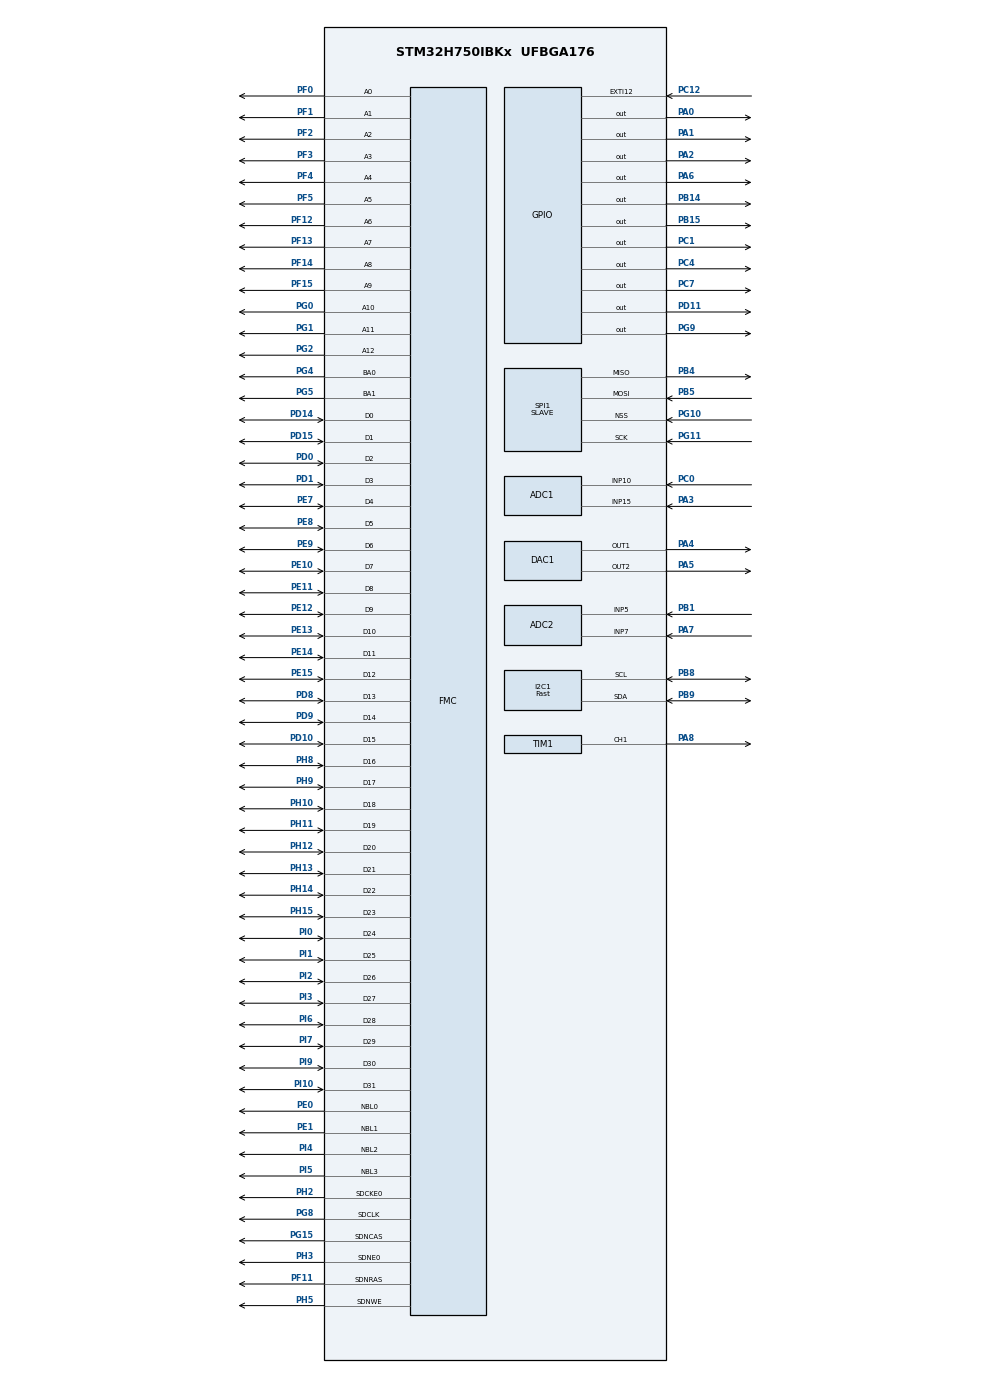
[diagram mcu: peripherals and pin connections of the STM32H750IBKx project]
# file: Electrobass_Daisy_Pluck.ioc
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ADC1.Channel-1\#ChannelRegularConversion=ADC_CHANNEL_10
ADC1.Channel-2\#ChannelRegularConversion=ADC_CHANNEL_15
ADC1.ClockPrescaler=ADC_CLOCK_ASYNC_DIV1
ADC1.ContinuousConvMode=ENABLE
ADC1.ConversionDataManagement=ADC_CONVERSIONDATA_DMA_CIRCULAR
ADC1.DMAAccessModeView=ENABLE
ADC1.EOCSelection=ADC_EOC_SEQ_CONV
ADC1.Mode=ADC_DUALMODE_REGSIMULT
ADC1.NbrOfConversion=2
ADC1.NbrOfConversionFlag=1
ADC1.OffsetNumber-1\#ChannelRegularConversion=ADC_OFFSET_NONE
ADC1.OffsetNumber-2\#ChannelRegularConversion=ADC_OFFSET_NONE
ADC1.Rank-1\#ChannelRegularConversion=1
ADC1.Rank-2\#ChannelRegularConversion=2
ADC1.SamplingTime-1\#ChannelRegularConversion=ADC_SAMPLETIME_64CYCLES_5
ADC1.SamplingTime-2\#ChannelRegularConversion=ADC_SAMPLETIME_64CYCLES_5
ADC1.TwoSamplingDelay=ADC_TWOSAMPLINGDELAY_4CYCLES
ADC1.master=1
ADC2.Channel-0\#ChannelRegularConversion=ADC_CHANNEL_7
ADC2.Channel-1\#ChannelRegularConversion=ADC_CHANNEL_5
ADC2.ContinuousConvMode=ENABLE
ADC2.ConversionDataManagement=ADC_CONVERSIONDATA_DR
ADC2.DMAAccessModeView=ENABLE
ADC2.EOCSelection=ADC_EOC_SEQ_CONV
ADC2.Mode=ADC_DUALMODE_REGSIMULT
ADC2.NbrOfConversion=2
ADC2.NbrOfConversionFlag=1
ADC2.OffsetNumber-0\#ChannelRegularConversion=ADC_OFFSET_NONE
ADC2.OffsetNumber-1\#ChannelRegularConversion=ADC_OFFSET_NONE
ADC2.OffsetSignedSaturation-0\#ChannelRegularConversion=DISABLE
ADC2.OffsetSignedSaturation-1\#ChannelRegularConversion=DISABLE
ADC2.Rank-0\#ChannelRegularConversion=1
ADC2.Rank-1\#ChannelRegularConversion=2
ADC2.SamplingTime-0\#ChannelRegularConversion=ADC_SAMPLETIME_64CYCLES_5
ADC2.SamplingTime-1\#ChannelRegularConversion=ADC_SAMPLETIME_64CYCLES_5
ADC2.TwoSamplingDelay=ADC_TWOSAMPLINGDELAY_4CYCLES
CORTEX_M7.CPU_DCache=Enabled
CORTEX_M7.CPU_ICache=Enabled
DAC1.DAC_Channel-DAC_OUT1=DAC_CHANNEL_1
DAC1.DAC_Channel-DAC_OUT2=DAC_CHANNEL_2
Dma.ADC1.0.Direction=DMA_PERIPH_TO_MEMORY
Dma.ADC1.0.EventEnable=DISABLE
Dma.ADC1.0.FIFOMode=DMA_FIFOMODE_ENABLE
Dma.ADC1.0.FIFOThreshold=DMA_FIFO_THRESHOLD_1QUARTERFULL
Dma.ADC1.0.Instance=DMA1_Stream0
Dma.ADC1.0.MemBurst=DMA_MBURST_SINGLE
Dma.ADC1.0.MemDataAlignment=DMA_MDATAALIGN_WORD
Dma.ADC1.0.MemInc=DMA_MINC_ENABLE
Dma.ADC1.0.Mode=DMA_CIRCULAR
Dma.ADC1.0.PeriphBurst=DMA_PBURST_SINGLE
Dma.ADC1.0.PeriphDataAlignment=DMA_PDATAALIGN_WORD
Dma.ADC1.0.PeriphInc=DMA_PINC_DISABLE
Dma.ADC1.0.Polarity=HAL_DMAMUX_REQ_GEN_RISING
Dma.ADC1.0.Priority=DMA_PRIORITY_HIGH
Dma.ADC1.0.RequestNumber=1
Dma.ADC1.0.SignalID=NONE
Dma.ADC1.0.SyncEnable=DISABLE
Dma.ADC1.0.SyncPolarity=HAL_DMAMUX_SYNC_NO_EVENT
Dma.ADC1.0.SyncRequestNumber=1
Dma.ADC1.0.SyncSignalID=NONE
Dma.Request0=ADC1
Dma.Request1=SPI1_RX
Dma.Request2=SPI1_TX
Dma.SPI1_RX.1.Direction=DMA_PERIPH_TO_MEMORY
Dma.SPI1_RX.1.EventEnable=DISABLE
Dma.SPI1_RX.1.FIFOMode=DMA_FIFOMODE_ENABLE
Dma.SPI1_RX.1.FIFOThreshold=DMA_FIFO_THRESHOLD_1QUARTERFULL
Dma.SPI1_RX.1.Instance=DMA1_Stream1
Dma.SPI1_RX.1.MemBurst=DMA_MBURST_SINGLE
Dma.SPI1_RX.1.MemDataAlignment=DMA_MDATAALIGN_BYTE
Dma.SPI1_RX.1.MemInc=DMA_MINC_ENABLE
Dma.SPI1_RX.1.Mode=DMA_CIRCULAR
Dma.SPI1_RX.1.PeriphBurst=DMA_PBURST_SINGLE
Dma.SPI1_RX.1.PeriphDataAlignment=DMA_PDATAALIGN_BYTE
Dma.SPI1_RX.1.PeriphInc=DMA_PINC_DISABLE
Dma.SPI1_RX.1.Polarity=HAL_DMAMUX_REQ_GEN_RISING
Dma.SPI1_RX.1.Priority=DMA_PRIORITY_VERY_HIGH
Dma.SPI1_RX.1.RequestNumber=1
Dma.SPI1_RX.1.SignalID=NONE
Dma.SPI1_RX.1.SyncEnable=DISABLE
Dma.SPI1_RX.1.SyncPolarity=HAL_DMAMUX_SYNC_NO_EVENT
Dma.SPI1_RX.1.SyncRequestNumber=1
Dma.SPI1_RX.1.SyncSignalID=NONE
Dma.SPI1_TX.2.Direction=DMA_MEMORY_TO_PERIPH
Dma.SPI1_TX.2.EventEnable=DISABLE
Dma.SPI1_TX.2.FIFOMode=DMA_FIFOMODE_ENABLE
Dma.SPI1_TX.2.FIFOThreshold=DMA_FIFO_THRESHOLD_FULL
Dma.SPI1_TX.2.Instance=DMA1_Stream2
Dma.SPI1_TX.2.MemBurst=DMA_MBURST_INC16
Dma.SPI1_TX.2.MemDataAlignment=DMA_MDATAALIGN_BYTE
Dma.SPI1_TX.2.MemInc=DMA_MINC_ENABLE
Dma.SPI1_TX.2.Mode=DMA_CIRCULAR
Dma.SPI1_TX.2.PeriphBurst=DMA_PBURST_SINGLE
Dma.SPI1_TX.2.PeriphDataAlignment=DMA_PDATAALIGN_BYTE
Dma.SPI1_TX.2.PeriphInc=DMA_PINC_DISABLE
Dma.SPI1_TX.2.Polarity=HAL_DMAMUX_REQ_GEN_RISING
Dma.SPI1_TX.2.Priority=DMA_PRIORITY_VERY_HIGH
Dma.SPI1_TX.2.RequestNumber=1
Dma.SPI1_TX.2.SignalID=NONE
Dma.SPI1_TX.2.SyncEnable=DISABLE
Dma.SPI1_TX.2.SyncPolarity=HAL_DMAMUX_SYNC_NO_EVENT
Dma.SPI1_TX.2.SyncRequestNumber=1
Dma.SPI1_TX.2.SyncSignalID=NONE
I2C1.I2C_Rise_Time=300
I2C1.I2C_Speed_Mode=I2C_Fast
I2C1.Timing=0x30B00F2D
Mcu.Family=STM32H7
Mcu.Name=STM32H750IBKx
Mcu.Package=UFBGA176
NVIC.DMA1_Stream0_IRQn=true\:4\:0\:true\:false\:true\:false\:true\:true
NVIC.DMA1_Stream1_IRQn=true\:3\:0\:true\:false\:true\:false\:true\:true
NVIC.DMA1_Stream2_IRQn=true\:2\:0\:true\:false\:true\:false\:true\:true
NVIC.EXTI15_10_IRQn=true\:0\:0\:true\:false\:true\:true\:true\:true
NVIC.PriorityGroup=NVIC_PRIORITYGROUP_4
NVIC.SPI1_IRQn=true\:1\:0\:true\:false\:true\:false\:true\:true
PA0.GPIO_Speed=GPIO_SPEED_FREQ_LOW
PA0.Signal=GPIO_Output
PA1.GPIO_Speed=GPIO_SPEED_FREQ_LOW
PA1.Signal=GPIO_Output
PA13\ (JTMS/SWDIO).Mode=Trace_Asynchronous_SW
PA13\ (JTMS/SWDIO).Signal=DEBUG_JTMS-SWDIO
PA14\ (JTCK/SWCLK).Mode=Trace_Asynchronous_SW
PA14\ (JTCK/SWCLK).Signal=DEBUG_JTCK-SWCLK
PA2.Signal=GPIO_Output
PA3.Signal=ADCx_INP15
PA4.Signal=COMP_DAC11_group
PA5.Signal=COMP_DAC12_group
PA6.Signal=GPIO_Output
PA7.Signal=ADCx_INP7
PA8.Signal=S_TIM1_CH1
PB1.Signal=ADCx_INP5
PB14.Signal=GPIO_Output
PB15.Signal=GPIO_Output
PB3\ (JTDO/TRACESWO).Mode=Trace_Asynchronous_SW
PB3\ (JTDO/TRACESWO).Signal=DEBUG_JTDO-SWO
PB4\ (NJTRST).GPIO_Speed=GPIO_SPEED_FREQ_VERY_HIGH
PB4\ (NJTRST).Mode=Full_Duplex_Slave
PB4\ (NJTRST).Signal=SPI1_MISO
PB5.GPIO_Speed=GPIO_SPEED_FREQ_VERY_HIGH
PB5.Mode=Full_Duplex_Slave
PB5.Signal=SPI1_MOSI
PB8.Mode=I2C
PB8.Signal=I2C1_SCL
PB9.Mode=I2C
PB9.Signal=I2C1_SDA
PC0.Signal=ADCx_INP10
PC1.Signal=GPIO_Output
PC12.GPIO_ModeDefaultEXTI=GPIO_MODE_IT_RISING_FALLING
PC12.GPIO_PuPd=GPIO_NOPULL
PC12.Signal=GPXTI12
PC4.Signal=GPIO_Output
PC7.Signal=GPIO_Output
PD0.Signal=FMC_D2_DA2
PD1.Signal=FMC_D3_DA3
PD10.Signal=FMC_D15_DA15
PD11.GPIO_PuPd=GPIO_PULLDOWN
PD11.Signal=GPIO_Output
PD14.Signal=FMC_D0_DA0
PD15.Signal=FMC_D1_DA1
PD8.Signal=FMC_D13_DA13
PD9.Signal=FMC_D14_DA14
PE0.Signal=FMC_NBL0
PE1.Signal=FMC_NBL1
PE10.Signal=FMC_D7_DA7
PE11.Signal=FMC_D8_DA8
PE12.Signal=FMC_D9_DA9
PE13.Signal=FMC_D10_DA10
PE14.Signal=FMC_D11_DA11
PE15.Signal=FMC_D12_DA12
PE7.Signal=FMC_D4_DA4
PE8.Signal=FMC_D5_DA5
PE9.Signal=FMC_D6_DA6
PF0.Signal=FMC_A0
PF1.Signal=FMC_A1
PF11.Signal=FMC_SDNRAS
PF12.Signal=FMC_A6
PF13.Signal=FMC_A7
PF14.Signal=FMC_A8
PF15.Signal=FMC_A9
PF2.Signal=FMC_A2
PF3.Signal=FMC_A3
PF4.Signal=FMC_A4
PF5.Signal=FMC_A5
PG0.Signal=FMC_A10
PG1.Signal=FMC_A11
PG10.GPIO_Speed=GPIO_SPEED_FREQ_VERY_HIGH
PG10.Mode=NSS_Signal_Hard_Input
PG10.Signal=SPI1_NSS
PG11.GPIO_Speed=GPIO_SPEED_FREQ_VERY_HIGH
PG11.Mode=Full_Duplex_Slave
PG11.Signal=SPI1_SCK
PG15.Signal=FMC_SDNCAS
PG2.Signal=FMC_A12
PG4.Signal=FMC_A14_BA0
PG5.Signal=FMC_A15_BA1
PG8.Signal=FMC_SDCLK
PG9.Signal=GPIO_Output
PH0-OSC_IN\ (PH0).Mode=HSE-External-Oscillator
PH0-OSC_IN\ (PH0).Signal=RCC_OSC_IN
PH1-OSC_OUT\ (PH1).Mode=HSE-External-Oscillator
PH1-OSC_OUT\ (PH1).Signal=RCC_OSC_OUT
PH10.Signal=FMC_D18
PH11.Signal=FMC_D19
PH12.Signal=FMC_D20
PH13.Signal=FMC_D21
PH14.Signal=FMC_D22
PH15.Signal=FMC_D23
PH2.Mode=SdramChipSelect1_1
PH2.Signal=FMC_SDCKE0
PH3.Mode=SdramChipSelect1_1
PH3.Signal=FMC_SDNE0
PH5.Signal=FMC_SDNWE
PH8.Signal=FMC_D16
PH9.Signal=FMC_D17
PI0.Signal=FMC_D24
PI1.Signal=FMC_D25
PI10.Signal=FMC_D31
PI2.Signal=FMC_D26
PI3.Signal=FMC_D27
PI4.Signal=FMC_NBL2
PI5.Signal=FMC_NBL3
PI6.Signal=FMC_D28
PI7.Signal=FMC_D29
PI9.Signal=FMC_D30
ProjectManager.HeapSize=0x2000
ProjectManager.StackSize=0x4000
ProjectManager.TargetToolchain=STM32CubeIDE
RCC.ADCCLockSelection=RCC_ADCCLKSOURCE_PLL3
RCC.ADCFreq_Value=12288085.9375
RCC.APB1Freq_Value=120000000
RCC.APB2Freq_Value=120000000
RCC.APB3Freq_Value=120000000
RCC.APB4Freq_Value=120000000
RCC.CKPERSourceSelection=RCC_CLKPSOURCE_HSE
RCC.CortexFreq_Value=480000000
RCC.D1PPRE=RCC_APB3_DIV2
RCC.D2PPRE1=RCC_APB1_DIV2
RCC.D2PPRE2=RCC_APB2_DIV2
RCC.D3PPRE=RCC_APB4_DIV2
RCC.DIVM1=1
RCC.DIVM2=1
RCC.DIVM3=1
RCC.DIVN1=60
RCC.DIVN2=12
RCC.DIVN3=12
RCC.DIVP2=8
RCC.DIVP3=4
RCC.DIVQ1=6
RCC.DIVQ3=8
RCC.DIVR1=8
RCC.DIVR3=16
RCC.FMCCLockSelection=RCC_FMCCLKSOURCE_PLL2
RCC.HCLKFreq_Value=240000000
RCC.HPRE=RCC_HCLK_DIV2
RCC.HSE_VALUE=16000000
RCC.PLL2FRACN=4096
RCC.PLL3FRACN=2360
RCC.PLLFRACN=0
RCC.PLLSourceVirtual=RCC_PLLSOURCE_HSE
RCC.ProductRev=revV
RCC.QSPICLockSelection=RCC_QSPICLKSOURCE_PLL
RCC.SAI1CLockSelection=RCC_SAI1CLKSOURCE_PLL3
RCC.SAI23CLockSelection=RCC_SAI23CLKSOURCE_PLL3
RCC.SDMMC1CLockSelection=RCC_SDMMCCLKSOURCE_PLL2
RCC.SYSCLKFreq_VALUE=480000000
RCC.SYSCLKSource=RCC_SYSCLKSOURCE_PLLCLK
RCC.USBCLockSelection=RCC_USBCLKSOURCE_HSI48
RCC.USBFreq_Value=48000000
SH.ADCx_INP10.0=ADC1_INP10,IN10-Single-Ended
SH.ADCx_INP15.0=ADC1_INP15,IN15-Single-Ended
SH.ADCx_INP5.0=ADC2_INP5,IN5-Single-Ended
SH.ADCx_INP7.0=ADC2_INP7,IN7-Single-Ended
SH.COMP_DAC11_group.0=DAC1_OUT1,DAC_OUT1
SH.COMP_DAC12_group.0=DAC1_OUT2,DAC_OUT2
SH.FMC_A0.0=FMC_A0,13b-sda1
SH.FMC_A1.0=FMC_A1,13b-sda1
SH.FMC_A10.0=FMC_A10,13b-sda1
SH.FMC_A11.0=FMC_A11,13b-sda1
SH.FMC_A12.0=FMC_A12,13b-sda1
SH.FMC_A14_BA0.0=FMC_BA0,FourSdramBanks1
SH.FMC_A15_BA1.0=FMC_BA1,FourSdramBanks1
SH.FMC_A2.0=FMC_A2,13b-sda1
SH.FMC_A3.0=FMC_A3,13b-sda1
SH.FMC_A4.0=FMC_A4,13b-sda1
SH.FMC_A5.0=FMC_A5,13b-sda1
SH.FMC_A6.0=FMC_A6,13b-sda1
SH.FMC_A7.0=FMC_A7,13b-sda1
SH.FMC_A8.0=FMC_A8,13b-sda1
SH.FMC_A9.0=FMC_A9,13b-sda1
SH.FMC_D0_DA0.0=FMC_D0,sd-32b-d1
SH.FMC_D10_DA10.0=FMC_D10,sd-32b-d1
SH.FMC_D11_DA11.0=FMC_D11,sd-32b-d1
SH.FMC_D12_DA12.0=FMC_D12,sd-32b-d1
SH.FMC_D13_DA13.0=FMC_D13,sd-32b-d1
SH.FMC_D14_DA14.0=FMC_D14,sd-32b-d1
SH.FMC_D15_DA15.0=FMC_D15,sd-32b-d1
SH.FMC_D16.0=FMC_D16,sd-32b-d1
SH.FMC_D17.0=FMC_D17,sd-32b-d1
SH.FMC_D18.0=FMC_D18,sd-32b-d1
SH.FMC_D19.0=FMC_D19,sd-32b-d1
SH.FMC_D1_DA1.0=FMC_D1,sd-32b-d1
SH.FMC_D20.0=FMC_D20,sd-32b-d1
SH.FMC_D21.0=FMC_D21,sd-32b-d1
SH.FMC_D22.0=FMC_D22,sd-32b-d1
SH.FMC_D23.0=FMC_D23,sd-32b-d1
SH.FMC_D24.0=FMC_D24,sd-32b-d1
SH.FMC_D25.0=FMC_D25,sd-32b-d1
SH.FMC_D26.0=FMC_D26,sd-32b-d1
SH.FMC_D27.0=FMC_D27,sd-32b-d1
SH.FMC_D28.0=FMC_D28,sd-32b-d1
SH.FMC_D29.0=FMC_D29,sd-32b-d1
SH.FMC_D2_DA2.0=FMC_D2,sd-32b-d1
SH.FMC_D30.0=FMC_D30,sd-32b-d1
SH.FMC_D31.0=FMC_D31,sd-32b-d1
SH.FMC_D3_DA3.0=FMC_D3,sd-32b-d1
SH.FMC_D4_DA4.0=FMC_D4,sd-32b-d1
SH.FMC_D5_DA5.0=FMC_D5,sd-32b-d1
SH.FMC_D6_DA6.0=FMC_D6,sd-32b-d1
SH.FMC_D7_DA7.0=FMC_D7,sd-32b-d1
SH.FMC_D8_DA8.0=FMC_D8,sd-32b-d1
SH.FMC_D9_DA9.0=FMC_D9,sd-32b-d1
SH.FMC_NBL0.0=FMC_NBL0,Sd4ByteEnable1
SH.FMC_NBL1.0=FMC_NBL1,Sd4ByteEnable1
SH.FMC_NBL2.0=FMC_NBL2,Sd4ByteEnable1
SH.FMC_NBL3.0=FMC_NBL3,Sd4ByteEnable1
SH.FMC_SDCLK.0=FMC_SDCLK,13b-sda1
SH.FMC_SDNCAS.0=FMC_SDNCAS,13b-sda1
SH.FMC_SDNRAS.0=FMC_SDNRAS,13b-sda1
SH.FMC_SDNWE.0=FMC_SDNWE,13b-sda1
SH.S_TIM1_CH1.0=TIM1_CH1,Output Compare1 CH1
SPI1.DataSize=SPI_DATASIZE_8BIT
SPI1.Direction=SPI_DIRECTION_2LINES
SPI1.FifoThreshold=SPI_FIFO_THRESHOLD_16DATA
SPI1.Mode=SPI_MODE_SLAVE
SPI1.VirtualNSS=VM_NSSHARD
SPI1.VirtualType=VM_SLAVE
TIM1.Channel-Output\ Compare1\ CH1=TIM_CHANNEL_1
VP_RNG_VS_RNG.Mode=RNG_Activate
board=custom

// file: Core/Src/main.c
/* USER CODE BEGIN Header */
/**
  ******************************************************************************
  * @file           : main.c
  * @brief          : Main program body
  ******************************************************************************
  * @attention
  *
  * <h2><center>&copy; Copyright (c) 2021 STMicroelectronics.
  * All rights reserved.</center></h2>
  *
  * This software component is licensed by ST under Ultimate Liberty license
  * SLA0044, the "License"; You may not use this file except in compliance with
  * the License. You may obtain a copy of the License at:
  *                             www.st.com/SLA0044
  *
  ******************************************************************************
  */
/* USER CODE END Header */
#include "main.h"
#include "adc.h"
#include "dac.h"
#include "dma.h"
#include "i2c.h"
#include "rng.h"
#include "spi.h"
#include "tim.h"
#include "gpio.h"
#include "fmc.h"

/* USER CODE BEGIN Includes */
#include "leaf.h"
/* USER CODE END Includes */

/* USER CODE BEGIN PD */
#define SDRECORD 0
#define SAMPLE_RATE 48000

/* USER CODE END PD */

/* USER CODE BEGIN PV */
 uint8_t SPI_TX[32] __ATTR_RAM_D2;
 uint8_t SPI_RX[32] __ATTR_RAM_D2;

#define NUM_ADC_CHANNELS 4
#define ADC_FRAME_SIZE 1
#define ADC_BUFFER_SIZE ADC_FRAME_SIZE * 2
#define NUM_STRINGS 4

uint32_t ADC_values[2 * ADC_BUFFER_SIZE] __ATTR_RAM_D2;

#define FILTER_ORDER 1
#define ATODB_TABLE_SIZE 25000
#define ATODB_TABLE_SIZE_MINUS_ONE 24999

#define MEDIUM_MEM_SIZE 300000
char mediumMemory[MEDIUM_MEM_SIZE] __ATTR_RAM_D1;
tMempool mediumPool;

int smoothedInt[NUM_STRINGS];
int smoothedInt2[NUM_STRINGS];
int dbSmoothedInt[NUM_STRINGS];
int tempAbsInt[NUM_STRINGS];
float atodbTable[ATODB_TABLE_SIZE];
int storedMaximums[NUM_STRINGS] = {10000.0f, 10000.0f, 10000.0f, 10000.0f};
float storedMaxFloats[NUM_STRINGS];
volatile uint16_t stringPositions[NUM_ADC_CHANNELS];
volatile uint16_t stringTouchRH[NUM_ADC_CHANNELS];
volatile uint16_t stringTouchRHPrev[NUM_ADC_CHANNELS];
volatile uint16_t stringTouchLH[NUM_ADC_CHANNELS];
volatile int didPlucked[NUM_ADC_CHANNELS];
volatile int stringSounding[NUM_ADC_CHANNELS];

int howManyFrames = 48000;
int brokedIt = 0;
int didPlucked2[4];
int pluckDelay[4];
int pluckValues[4];

float Dsmoothed;
float Dsmoothed2;
float dbSmoothed2;

float stringScaling[4] = {2.0f, 1.3f, 0.9f, 0.4f};
float stringScaling2[4] = {1.20f, 1.4f, 0.9f, 0.5f};
int armed[NUM_STRINGS] = {0,0,0,0};
float prevdbSmoothed2[NUM_STRINGS];
int threshOut = 0;
int stringMaxes[NUM_STRINGS] = {0,0,0,0};
int downCounter[NUM_STRINGS];
int armedCounter[NUM_STRINGS];
float slopeStorage[NUM_STRINGS];

tHighpass opticalHighpass[NUM_ADC_CHANNELS][FILTER_ORDER];
tHighpass EMHighpass[4];
tVZFilter opticalLowpass[NUM_ADC_CHANNELS][FILTER_ORDER];
tSlide fastSlide[NUM_ADC_CHANNELS];
tSlide slowSlide[NUM_ADC_CHANNELS];
tThreshold threshold[NUM_ADC_CHANNELS];
LEAF leaf;
int counter = 0;

/* USER CODE END PV */

void SystemClock_Config(void);
void PeriphCommonClock_Config(void);
/* USER CODE BEGIN PFP */
void MPU_Conf(void);
float randomNumber(void);
/* USER CODE END PFP */

int main(void)
{
  /* USER CODE BEGIN 1 */
  MPU_Conf();
  /* USER CODE END 1 */

  /* Enable I-Cache---------------------------------------------------------*/
  SCB_EnableICache();

  /* Enable D-Cache---------------------------------------------------------*/
  SCB_EnableDCache();

  /* MCU Configuration--------------------------------------------------------*/

  /* Reset of all peripherals, Initializes the Flash interface and the Systick. */
  HAL_Init();

  /* Configure the system clock */
  SystemClock_Config();

/* Configure the peripherals common clocks */
  PeriphCommonClock_Config();

  /* Initialize all configured peripherals */
  MX_GPIO_Init();
  MX_DMA_Init();
  MX_ADC1_Init();
  MX_FMC_Init();
  MX_SPI1_Init();
  MX_TIM1_Init();
  MX_I2C1_Init();
  MX_RNG_Init();
  MX_ADC2_Init();
  MX_DAC1_Init();
  /* USER CODE BEGIN 2 */
  //HAL_GPIO_WritePin(GPIOA, GPIO_PIN_0, GPIO_PIN_RESET);
  uint32_t tempFPURegisterVal = __get_FPSCR();
  tempFPURegisterVal |= (1<<24); // set the FTZ (flush-to-zero) bit in the FPU control register
  __set_FPSCR(tempFPURegisterVal);

  while(HAL_GPIO_ReadPin(GPIOC, GPIO_PIN_12) == 0)
  {
	  ;
  }
  for (int i = 0; i < 32; i++)
  {
	  SPI_TX[i] = i;
  }

  for (int i = 0; i < 8; i++)
  {
	  SPI_TX[i] = 0;
  }
  for (int i = 16; i < 24; i++)
  {
	  SPI_TX[i] = 0;
  }

  //HAL_SPI_TransmitReceive_DMA(&hspi1, SPI_TX, SPI_RX, 32);
  HAL_SPI_TransmitReceive_IT(&hspi1, SPI_TX, SPI_RX, 16);
  //HAL_Delay(10);

  LEAF_init(&leaf, SAMPLE_RATE, mediumMemory, MEDIUM_MEM_SIZE, &randomNumber);

  for (int i = 0; i < NUM_ADC_CHANNELS; i++)
  {
  	tThreshold_init(&threshold[i],700.0f, 900.0f, &leaf);//.01 .05
  	tSlide_init(&fastSlide[i],1.0f,500.0f, &leaf); //500
  	tSlide_init(&slowSlide[i],1.0f,700.0f, &leaf); //500 //1000

  	storedMaxFloats[i] = (65535.0f / storedMaximums[i]);
  	for (int j = 0; j < FILTER_ORDER; j++)
  	{
  		tVZFilter_init(&opticalLowpass[i][j], Lowpass, 1000.0f, 0.2f, &leaf); //1000
  		tHighpass_init(&opticalHighpass[i][j], 60.0f, &leaf); //100
  	}
  }
  HAL_DAC_Start(&hdac1, DAC_CHANNEL_1);
  HAL_DAC_Start(&hdac1, DAC_CHANNEL_2);
  LEAF_generate_atodb(atodbTable, ATODB_TABLE_SIZE, 0.0f, 1.0f);
  HAL_ADC_Start(&hadc2);
  HAL_ADCEx_MultiModeStart_DMA(&hadc1,(uint32_t*)&ADC_values,2 * ADC_BUFFER_SIZE);

  /* USER CODE END 2 */

  /* Infinite loop */
  while (1)
  {

    /* USER CODE BEGIN 3 */

	  //HAL_GPIO_WritePin(GPIOC, GPIO_PIN_7, GPIO_PIN_SET);

	  HAL_Delay(100);

	  //HAL_GPIO_WritePin(GPIOC, GPIO_PIN_7, GPIO_PIN_RESET);
  }
  /* USER CODE END 3 */
}

void SystemClock_Config(void)
{
  RCC_OscInitTypeDef RCC_OscInitStruct = {0};
  RCC_ClkInitTypeDef RCC_ClkInitStruct = {0};

  /** Supply configuration update enable
  */
  HAL_PWREx_ConfigSupply(PWR_LDO_SUPPLY);

  /** Configure the main internal regulator output voltage
  */
  __HAL_PWR_VOLTAGESCALING_CONFIG(PWR_REGULATOR_VOLTAGE_SCALE1);

  while(!__HAL_PWR_GET_FLAG(PWR_FLAG_VOSRDY)) {}

  __HAL_RCC_SYSCFG_CLK_ENABLE();
  __HAL_PWR_VOLTAGESCALING_CONFIG(PWR_REGULATOR_VOLTAGE_SCALE0);

  while(!__HAL_PWR_GET_FLAG(PWR_FLAG_VOSRDY)) {}

  /** Macro to configure the PLL clock source
  */
  __HAL_RCC_PLL_PLLSOURCE_CONFIG(RCC_PLLSOURCE_HSE);

  /** Initializes the RCC Oscillators according to the specified parameters
  * in the RCC_OscInitTypeDef structure.
  */
  RCC_OscInitStruct.OscillatorType = RCC_OSCILLATORTYPE_HSI48|RCC_OSCILLATORTYPE_HSE;
  RCC_OscInitStruct.HSEState = RCC_HSE_ON;
  RCC_OscInitStruct.HSI48State = RCC_HSI48_ON;
  RCC_OscInitStruct.PLL.PLLState = RCC_PLL_ON;
  RCC_OscInitStruct.PLL.PLLSource = RCC_PLLSOURCE_HSE;
  RCC_OscInitStruct.PLL.PLLM = 1;
  RCC_OscInitStruct.PLL.PLLN = 60;
  RCC_OscInitStruct.PLL.PLLP = 2;
  RCC_OscInitStruct.PLL.PLLQ = 6;
  RCC_OscInitStruct.PLL.PLLR = 8;
  RCC_OscInitStruct.PLL.PLLRGE = RCC_PLL1VCIRANGE_3;
  RCC_OscInitStruct.PLL.PLLVCOSEL = RCC_PLL1VCOWIDE;
  RCC_OscInitStruct.PLL.PLLFRACN = 0;
  if (HAL_RCC_OscConfig(&RCC_OscInitStruct) != HAL_OK)
  {
    Error_Handler();
  }

  /** Initializes the CPU, AHB and APB buses clocks
  */
  RCC_ClkInitStruct.ClockType = RCC_CLOCKTYPE_HCLK|RCC_CLOCKTYPE_SYSCLK
                              |RCC_CLOCKTYPE_PCLK1|RCC_CLOCKTYPE_PCLK2
                              |RCC_CLOCKTYPE_D3PCLK1|RCC_CLOCKTYPE_D1PCLK1;
  RCC_ClkInitStruct.SYSCLKSource = RCC_SYSCLKSOURCE_PLLCLK;
  RCC_ClkInitStruct.SYSCLKDivider = RCC_SYSCLK_DIV1;
  RCC_ClkInitStruct.AHBCLKDivider = RCC_HCLK_DIV2;
  RCC_ClkInitStruct.APB3CLKDivider = RCC_APB3_DIV2;
  RCC_ClkInitStruct.APB1CLKDivider = RCC_APB1_DIV2;
  RCC_ClkInitStruct.APB2CLKDivider = RCC_APB2_DIV2;
  RCC_ClkInitStruct.APB4CLKDivider = RCC_APB4_DIV2;

  if (HAL_RCC_ClockConfig(&RCC_ClkInitStruct, FLASH_LATENCY_4) != HAL_OK)
  {
    Error_Handler();
  }
}

void PeriphCommonClock_Config(void)
{
  RCC_PeriphCLKInitTypeDef PeriphClkInitStruct = {0};

  /** Initializes the peripherals clock
  */
  PeriphClkInitStruct.PeriphClockSelection = RCC_PERIPHCLK_ADC;
  PeriphClkInitStruct.PLL3.PLL3M = 1;
  PeriphClkInitStruct.PLL3.PLL3N = 12;
  PeriphClkInitStruct.PLL3.PLL3P = 4;
  PeriphClkInitStruct.PLL3.PLL3Q = 8;
  PeriphClkInitStruct.PLL3.PLL3R = 16;
  PeriphClkInitStruct.PLL3.PLL3RGE = RCC_PLL3VCIRANGE_3;
  PeriphClkInitStruct.PLL3.PLL3VCOSEL = RCC_PLL3VCOWIDE;
  PeriphClkInitStruct.PLL3.PLL3FRACN = 2360;
  PeriphClkInitStruct.AdcClockSelection = RCC_ADCCLKSOURCE_PLL3;
  if (HAL_RCCEx_PeriphCLKConfig(&PeriphClkInitStruct) != HAL_OK)
  {
    Error_Handler();
  }
}

/* USER CODE BEGIN 4 */
void MPU_Conf(void)
 {
	//code from Keshikan https://github.com/keshikan/STM32H7_DMA_sample
  //Thanks, Keshikan! This solves the issues with accessing the SRAM in the D2 area properly. -JS
	//should test the different possible settings to see what works best while avoiding needing to manually clear the cache -JS

	MPU_Region_InitTypeDef MPU_InitStruct;

	  HAL_MPU_Disable();

	  MPU_InitStruct.Enable = MPU_REGION_ENABLE;

	  //D2 Domain�SRAM1
	  MPU_InitStruct.BaseAddress = 0x30000000;
	  // Increased region size to 256k. In Keshikan's code, this was 512 bytes (that's all that application needed).
	  // Each audio buffer takes up the frame size * 8 (16 bits makes it *2 and stereo makes it *2 and double buffering makes it *2)
	  // So a buffer size for read/write of 4096 would take up 64k = 4096*8 * 2 (read and write).
	  // I increased that to 256k so that there would be room for the ADC knob inputs and other peripherals that might require DMA access.
	  // we have a total of 256k in SRAM1 (128k, 0x30000000-0x30020000) and SRAM2 (128k, 0x30020000-0x3004000) of D2 domain.
	  // There is an SRAM3 in D2 domain as well (32k, 0x30040000-0x3004800) that is currently not mapped by the MPU (memory protection unit) controller.

	  MPU_InitStruct.Size = MPU_REGION_SIZE_256KB;

	  MPU_InitStruct.AccessPermission = MPU_REGION_FULL_ACCESS;

	  //AN4838
	  MPU_InitStruct.TypeExtField = MPU_TEX_LEVEL1;
	  MPU_InitStruct.IsCacheable = MPU_ACCESS_NOT_CACHEABLE;
	  MPU_InitStruct.IsBufferable = MPU_ACCESS_NOT_BUFFERABLE;
	  MPU_InitStruct.IsShareable = MPU_ACCESS_SHAREABLE;

	  //Shared Device
//	  MPU_InitStruct.TypeExtField = MPU_TEX_LEVEL0;
//	  MPU_InitStruct.IsCacheable = MPU_ACCESS_NOT_CACHEABLE;
//	  MPU_InitStruct.IsBufferable = MPU_ACCESS_BUFFERABLE;
//	  MPU_InitStruct.IsShareable = MPU_ACCESS_SHAREABLE;

	  MPU_InitStruct.Number = MPU_REGION_NUMBER0;

	  MPU_InitStruct.SubRegionDisable = 0x00;

	  MPU_InitStruct.DisableExec = MPU_INSTRUCTION_ACCESS_DISABLE;

	  HAL_MPU_ConfigRegion(&MPU_InitStruct);

	  //now set up D3 domain RAM

	  MPU_InitStruct.Enable = MPU_REGION_ENABLE;

	  //D3 Domain�SRAM
	  MPU_InitStruct.BaseAddress = 0x38000000;

	  MPU_InitStruct.Size = MPU_REGION_SIZE_64KB;

	  MPU_InitStruct.AccessPermission = MPU_REGION_FULL_ACCESS;

	  //AN4838
	  MPU_InitStruct.TypeExtField = MPU_TEX_LEVEL1;
	  MPU_InitStruct.IsCacheable = MPU_ACCESS_CACHEABLE;
	  MPU_InitStruct.IsBufferable = MPU_ACCESS_BUFFERABLE;
	  MPU_InitStruct.IsShareable = MPU_ACCESS_SHAREABLE;

	  //Shared Device
 //	  MPU_InitStruct.TypeExtField = MPU_TEX_LEVEL0;
 //	  MPU_InitStruct.IsCacheable = MPU_ACCESS_NOT_CACHEABLE;
 //	  MPU_InitStruct.IsBufferable = MPU_ACCESS_BUFFERABLE;
 //	  MPU_InitStruct.IsShareable = MPU_ACCESS_SHAREABLE;

	  MPU_InitStruct.Number = MPU_REGION_NUMBER1;

	  MPU_InitStruct.SubRegionDisable = 0x00;

	  MPU_InitStruct.DisableExec = MPU_INSTRUCTION_ACCESS_ENABLE;

	  HAL_MPU_ConfigRegion(&MPU_InitStruct);

	  HAL_MPU_Enable(MPU_PRIVILEGED_DEFAULT);
}

float randomNumber(void) {

	uint32_t rand;
	HAL_RNG_GenerateRandomNumber(&hrng, &rand);
	float num = (float)rand * INV_TWO_TO_32;
	return num;
}

volatile int totalMaximums[NUM_STRINGS];
volatile float pickupMaximums[NUM_STRINGS] = {0.0f, 0.0f, 0.0f, 0.0f};
volatile int outcountdown[NUM_STRINGS] = {-1,-1,-1,-1};

int stringStates[4];
uint16_t stringPressed[4];
int spiBuffer = 0;
int didPluckedWaiting[4] = {0,0,0,0};
int didPluckedWaitingCounter[4] = {0,0,0,0};
int openstrings[4] = {0,0,0,0};
int hammerOnWait[4] = {0,0,0,0};
int hammerOnWaiting[4] = {0,0,0,0};
int pullOffWait[4] = {-1,-1,-1,-1};

uint8_t stringFrozen[4] = {0,0,0,0};
int lastPlucked[4];

int test1 = 0;
int test2 = 0;
int test3 = 0;
int test4 = 0;
int test5 = 0;

uint16_t testAnalog = 0;
int testAnalog2 = 0;

float maxFlo[NUM_STRINGS] = {0.0f,0.0f,0.0f,0.0f};
float minFlo[NUM_STRINGS] = {0.0f,0.0f,0.0f,0.0f};
uint8_t numQuietFails[NUM_STRINGS] = {0,0,0,0};
uint8_t countingDown[NUM_STRINGS] = {0,0,0,0};
uint16_t pluckWaitCount[NUM_STRINGS] = {0,0,0,0};
uint8_t pluckWaitState[NUM_STRINGS] = {0,0,0,0};

int attackDetectPeak2 (int whichString, uint16_t tempInt)
{
	float output = -1;

	//if (stringTouchRH[whichString])
	{
		//stringSounding[whichString] = 0;
	}

	if (whichString == 0)
	{
		//HAL_GPIO_WritePin(GPIOD, GPIO_PIN_11, GPIO_PIN_RESET);
		//HAL_GPIO_WritePin(GPIOA, GPIO_PIN_0, GPIO_PIN_RESET);
	}
	float tempSamp = (((float)tempInt - TWO_TO_15) * INV_TWO_TO_15);

	for (int k = 0; k < FILTER_ORDER; k++)
	{
		// a highpass filter, remove any slow moving signal (effectively centers the signal around zero and gets rid of the signal that isn't high frequency vibration) cutoff of 100Hz, // applied 8 times to get rid of a lot of low frequency bumbling around
		tempSamp = tHighpass_tick(&opticalHighpass[whichString][k], tempSamp * 0.5f);
		tempSamp = tVZFilter_tickEfficient(&opticalLowpass[whichString][k], tempSamp);
	}
/*
	if (tempSamp > 1.0f)
	{
		HAL_GPIO_TogglePin(GPIOD, GPIO_PIN_11);
	}
	else if (tempSamp < -1.0f)
	{
		HAL_GPIO_TogglePin(GPIOD, GPIO_PIN_11);
	}
	*/
	testAnalog2 = (tempSamp * TWO_TO_15) + TWO_TO_15;

	//float tempAbs = fabsf(tempSamp);
	//take only postive half of wave, since negative half is messed up and clipped by poor opamp choice on this prototype
	float tempAbs  = LEAF_clip(0.0f, tempSamp, 1.0f);
	tempAbsInt[whichString] = (tempAbs * (TWO_TO_16 - 1));
	Dsmoothed = tSlide_tick(&fastSlide[whichString], tempAbs);
	smoothedInt[whichString] = (Dsmoothed * (TWO_TO_16 - 1));
	Dsmoothed2 = tSlide_tick(&slowSlide[whichString], Dsmoothed);

	Dsmoothed2 = LEAF_clip(0.0f, Dsmoothed2, 1.0f);
	smoothedInt2[whichString] = (Dsmoothed2 * (TWO_TO_16 - 1));

	//dbSmoothed2 = atodb(Dsmoothed2);
	//80db
	dbSmoothed2 = LEAF_clip(-120.0f, atodbTable[(uint32_t)(Dsmoothed2 * ATODB_TABLE_SIZE_MINUS_ONE)], 12.0f);
	dbSmoothedInt[whichString] = dbSmoothed2 * 100.0f;
	//dbSmoothed2 = LEAF_clip(-50.f, dbSmoothed2, 12.0f);
	//get the slope
	float slope = (dbSmoothed2 - prevdbSmoothed2[whichString]);
	slopeStorage[whichString] = slope;
	float integerVersion = Dsmoothed2 * (TWO_TO_16 - 1);
	//uint16_t toDac1 = ((uint16_t)LEAF_clip(-2048.0f, slope * 100.0f, 2048.0f))+2048;
	uint16_t toDac1 = LEAF_clip(-4095, dbSmoothedInt[whichString]/3, 0) + 4095;
	//uint16_t toDac2 = smoothedInt2[whichString] >> 4;
	//uint16_t toDac2 = LEAF_clip(-2047, slope * 200.0f , 2047) + 2047;
	uint16_t toDac2 = TWO_TO_12 * (2.0f * maxFlo[whichString]);// - minFlo[whichString]);;

	if (whichString == 0)
	{
		//HAL_DAC_SetValue(&hdac1, DAC_CHANNEL_1, DAC_ALIGN_12B_R, testAnalog2 >> 4);
		//HAL_DAC_SetValue(&hdac1, DAC_CHANNEL_2, DAC_ALIGN_12B_R, smoothedInt2[whichString] >> 4);
		HAL_DAC_SetValue(&hdac1, DAC_CHANNEL_2, DAC_ALIGN_12B_R, toDac2);
	}
	if (whichString == 0)
	{
		HAL_DAC_SetValue(&hdac1, DAC_CHANNEL_1, DAC_ALIGN_12B_R, toDac1);
	}

	if (pluckWaitState[whichString] > 0)
	{
		pluckWaitCount[whichString]++;
		if (pluckWaitCount[whichString] > 1000)
		{
			pluckWaitState[whichString] = 0;
		}
	}

	threshOut = tThreshold_tick(&threshold[whichString], integerVersion);
	if (whichString == 0)
	{
		if (stringTouchRH[whichString])
		{
			HAL_GPIO_WritePin(GPIOC, GPIO_PIN_4, GPIO_PIN_SET);
		}
		else
		{
			HAL_GPIO_WritePin(GPIOC, GPIO_PIN_4, GPIO_PIN_RESET);
		}

		if (threshOut > 0)
		{
			//HAL_GPIO_WritePin(GPIOA, GPIO_PIN_1, GPIO_PIN_SET);
		}
		else
		{
			//HAL_GPIO_WritePin(GPIOA, GPIO_PIN_1, GPIO_PIN_RESET);
		}

		HAL_GPIO_WritePin(GPIOA, GPIO_PIN_6, stringSounding[0]);

	}
	//if (whichString == 1)
	{
		//if (threshOut > 0)
		{
			//HAL_GPIO_WritePin(GPIOD, GPIO_PIN_11, GPIO_PIN_SET);
		}
		//else
		{
			//HAL_GPIO_WritePin(GPIOD, GPIO_PIN_11, GPIO_PIN_RESET);
		}
	}
	if ((slope > 0.14f) && (threshOut > 0) && (!armed[whichString]) && (stringSounding[whichString] == 0))
	{
		armed[whichString] = 1;
		pickupMaximums[whichString] = 0.0f;
		stringMaxes[whichString] = 0;
		maxFlo[whichString] = 0.0f;
		minFlo[whichString] = 0.0f;
		countingDown[whichString] = 0;
		outcountdown[whichString] = -1;
		if (whichString == 0)
		{
			HAL_GPIO_WritePin(GPIOC, GPIO_PIN_1, GPIO_PIN_SET);
			//HAL_GPIO_WritePin(GPIOA, GPIO_PIN_6, GPIO_PIN_RESET);
		}
		numQuietFails[whichString] = 0;
	}

	if (armed[whichString] == 1)
	{
		if (tempSamp > maxFlo[whichString])
		{
			maxFlo[whichString] = tempSamp;
		}
		if (tempSamp < minFlo[whichString])
		{
			minFlo[whichString] = tempSamp;
		}

		if (integerVersion > stringMaxes[whichString])
		{
			stringMaxes[whichString] = integerVersion;
		}
		armedCounter[whichString]++;

		//HAL_GPIO_WritePin(GPIOA, GPIO_PIN_6, GPIO_PIN_RESET);

		if (slope <= 0.0f)
		{
			downCounter[whichString]++;
			//if (whichString == 1)
			{
				//HAL_GPIO_WritePin(GPIOB, GPIO_PIN_8, GPIO_PIN_SET);
			}
		}
		if (slope > 0.01f)
		{
			downCounter[whichString] = 0;
			//if (whichString == 1)
			{
				//HAL_GPIO_WritePin(GPIOB, GPIO_PIN_8, GPIO_PIN_RESET);
			}
		}
		if (whichString == 0)
		{
			//HAL_DAC_SetValue(&hdac1, DAC_CHANNEL_1, DAC_ALIGN_12B_R, downCounter[whichString]*5);
		}

		if (downCounter[whichString] > 80) // was 100
		{

			if ((!stringTouchRH[whichString]) && (stringSounding[whichString] == 0))
			{
				//output = (float)stringMaxes[whichString];
				output = TWO_TO_16 * (2.0f * maxFlo[whichString]);// - minFlo[whichString]);

				if (storedMaximums[whichString] < output)
				{
					storedMaximums[whichString] = output; // TODO:new
				}

				output = LEAF_clip(0.0f, output, 65535.0f);

				testAnalog = output;

				armed[whichString] = 0;
				armedCounter[whichString] = 0;
				downCounter[whichString] = 0;
				stringMaxes[whichString] = 0;
				pluckWaitState[whichString] = 1;
				pluckWaitCount[whichString] = 0;
				if ((whichString == 0) && (output > 0))
				{
					//HAL_GPIO_WritePin(GPIOD, GPIO_PIN_11, GPIO_PIN_SET);
					HAL_GPIO_WritePin(GPIOA, GPIO_PIN_6, GPIO_PIN_SET);

					//HAL_GPIO_WritePin(GPIOA, GPIO_PIN_6, GPIO_PIN_SET);
				}
				if (whichString == 0)
				{
					HAL_GPIO_WritePin(GPIOC, GPIO_PIN_1, GPIO_PIN_RESET);
					//HAL_GPIO_WritePin(GPIOA, GPIO_PIN_0, GPIO_PIN_SET);
				}
				if (whichString == 0)
				{
					//HAL_GPIO_WritePin(GPIOC, GPIO_PIN_4, GPIO_PIN_RESET);
				}
			}

			if (downCounter[whichString] > 200)
			{
				armed[whichString] = 0;
				armedCounter[whichString] = 0;
				downCounter[whichString] = 0;
				stringMaxes[whichString] = 0;
				pluckWaitState[whichString] = 0;
				pluckWaitCount[whichString] = 0;
				if (whichString == 0)
				{
					HAL_GPIO_WritePin(GPIOC, GPIO_PIN_1, GPIO_PIN_RESET);
					//HAL_GPIO_WritePin(GPIOA, GPIO_PIN_0, GPIO_PIN_SET);
				}
				if (whichString == 0)
				{
					//HAL_GPIO_WritePin(GPIOC, GPIO_PIN_4, GPIO_PIN_RESET);
				}
			}
		}
	}
	//HAL_GPIO_WritePin(GPIOA, GPIO_PIN_0, pluckWaitState[0]);
	prevdbSmoothed2[whichString] = dbSmoothed2;
	return (int)output;
}

uint8_t SPI_lock = 0;
uint8_t stringChanged[NUM_STRINGS] = {0,0,0,0};
uint16_t stringChangeWaiting[NUM_STRINGS] = {0,0,0,0};
volatile uint16_t waitingPlucks[NUM_STRINGS][32] = {0};
uint16_t waitingPlucksSPI[NUM_STRINGS][32] = {0};
uint8_t waitingForSPIReady[NUM_STRINGS] = {0,0,0,0};
uint16_t numFramesSinceSPI = 0;

void ADC_Frame(int offset)
{
	uint16_t adcBytes[4];
	HAL_GPIO_WritePin(GPIOA, GPIO_PIN_1, GPIO_PIN_SET);
	adcBytes[0] = ADC_values[offset*2] & 65535;
	adcBytes[1] = ADC_values[offset*2 + 1] & 65535;
	adcBytes[2] = ADC_values[offset*2] >> 16;
	adcBytes[3] = ADC_values[offset*2 + 1] >> 16;

	//HAL_DAC_SetValue(&hdac1, DAC_CHANNEL_2, DAC_ALIGN_12B_R, stringPressed[0] >> 4);
	//HAL_DAC_SetValue(&hdac1, DAC_CHANNEL_1, DAC_ALIGN_12B_R, stringTouchLH[0] * 4095);

	for (int i = offset; i < ADC_FRAME_SIZE + offset; i++)
	{
		if (howManyFrames > 0)
		{
			howManyFrames--;
		}
		for (int j = 0; j < 4; j++)
		{
			uint16_t tempInt = adcBytes[j];

			didPlucked[j] = attackDetectPeak2(j, tempInt);

			if (howManyFrames == 0)
			{

				//check that we don't have any waiting pluck messages that happened while SPI array was locked
				while ((waitingForSPIReady[j] > 0) && (!SPI_lock))
				{
					//for each waiting SPI message, add it to the list that the SPI interrupt will go through
					waitingPlucks[j][stringChangeWaiting[j]] = waitingPlucksSPI[j][waitingForSPIReady[j]];
					stringChangeWaiting[j] = (stringChangeWaiting[j] + 1) & 31; //add one but wrap to make sure we don't write outside of array bounds

					for (int i = waitingForSPIReady[j]; i > 0; i--)
					{
						waitingPlucks[j][i-1]  = waitingPlucks[j][i];
					}
					waitingForSPIReady[j]--;
				}

				if (((didPlucked[j] > 0)) && (!stringSounding[j]) && (!stringTouchRH[j]))
				{
					if (didPlucked[j] > totalMaximums[j])
					{
						totalMaximums[j] = didPlucked[j];
					}

					if (didPlucked[j] > 65535)
					{
						didPlucked[j] = 65535;
					}

					stringStates[j] = didPlucked[j];

					//a pluck happened!
					//The ADC frames run much faster than the SPI frames (which are running at between 400us and 800us)

					//check that the data array for the SPI bus is not in use before writing
					if (!SPI_lock)
					{
						waitingPlucks[j][stringChangeWaiting[j]] = stringStates[j];
						stringChangeWaiting[j] = (stringChangeWaiting[j] + 1) & 31; //add one but wrap to make sure we don't write outside of array bounds
					}
					else
					{
						//if that data array was busy, write into a different temp storage array until we are able to transfer that data
						waitingPlucksSPI[j][waitingForSPIReady[j]] = stringStates[j];
						waitingForSPIReady[j]++;
					}

					if (j == 0)
					{
						HAL_GPIO_WritePin(GPIOC, GPIO_PIN_7, GPIO_PIN_SET);
					}
					SPI_TX[j*2] = (uint8_t) (waitingPlucks[j][0] >> 8); //high byte
					SPI_TX[j*2+1] = (uint8_t) (waitingPlucks[j][0] & 0xff); //low byte

					if (numFramesSinceSPI < 15) //we need to adjust this if the SPI to ADC frame speed relationship changes. Currently around 23 frames of ADC per SPI frame so this is making sure that we're not too close to another upcoming SPI frame if we are going to mess with the buffer
					{
						HAL_SPI_Abort(&hspi1);
						HAL_SPI_TransmitReceive_IT(&hspi1, SPI_TX, SPI_RX, 16);
					}

					//changeHappened = 1;
					stringSounding[j] = 1;
					lastPlucked[j] = stringStates[j];
				}

				//if you touch with right hand that's a mute
				else if ((stringTouchRH[j]) && (stringSounding[j]))
				{
					//a note-off happened! send a message over SPI to the other ICs

					if (j == 0)
					{
						HAL_GPIO_WritePin(GPIOC, GPIO_PIN_7, GPIO_PIN_RESET);
					}

					stringStates[j] = 0;
					//changeHappened = 1;
					pickupMaximums[j] = 0.0f;
					stringSounding[j] = 0;
					//a note off happened!
					//check that the data array for the SPI bus is not in use before writing
					if (!SPI_lock)
					{
						waitingPlucks[j][stringChangeWaiting[j]] = stringStates[j];
						stringChangeWaiting[j] = (stringChangeWaiting[j] + 1) & 31; //add one but wrap to make sure we don't write outside of array bounds

					}
					else
					{
						//if that data array was busy, write into a different temp storage array until we are able to transfer that data
						waitingPlucksSPI[j][waitingForSPIReady[j]] = stringStates[j];
						waitingForSPIReady[j]++;
					}
					SPI_TX[j*2] = (uint8_t) (waitingPlucks[j][0] >> 8); //high byte
					SPI_TX[j*2+1] = (uint8_t) (waitingPlucks[j][0] & 0xff); //low byte
					if (numFramesSinceSPI < 15) //we need to adjust this if the SPI to ADC frame speed relationship changes. Currently around 23 frames of ADC per SPI frame so this is making sure that we're not too close to another upcoming SPI frame if we are going to mess with the buffer
					{
						HAL_SPI_Abort(&hspi1);
						HAL_SPI_TransmitReceive_IT(&hspi1, SPI_TX, SPI_RX, 16);
					}
				}
				stringTouchRHPrev[j] = stringTouchRH[j];

			}

		}

	}
	numFramesSinceSPI++;
	HAL_GPIO_WritePin(GPIOA, GPIO_PIN_1, GPIO_PIN_RESET);
}

void HAL_ADC_ConvCpltCallback(ADC_HandleTypeDef *hadc)
{

	if (hadc == &hadc1)
	{
		ADC_Frame(ADC_FRAME_SIZE);
	}

}
void HAL_ADC_ConvHalfCpltCallback(ADC_HandleTypeDef *hadc)
{
	if (hadc == &hadc1)
	{
		ADC_Frame(0);
	}

}
void HAL_ADC_Error(ADC_HandleTypeDef *hadc)
{

}

void HAL_SPI_TxRxCpltCallback(SPI_HandleTypeDef *hspi)
{
	  /* Enable Tx DMA Request */
	//__HAL_DMA_DISABLE(&hdma_spi1_tx);
	spiBuffer = 0;
	numFramesSinceSPI = 0;
	//HAL_GPIO_WritePin(GPIOB, GPIO_PIN_4, GPIO_PIN_RESET);
    HAL_GPIO_WritePin(GPIOA, GPIO_PIN_0, GPIO_PIN_SET);
    SPI_lock = 1;

	SPI_TX[8+(16*spiBuffer)] = 0x00; //check byte
	SPI_TX[9+(16*spiBuffer)] = 0x00; //check byte
	for (int j = 0; j < 4; j++)
	{
		stringTouchRH[j] = (SPI_RX[8] >> j) & 1;
		int currentnumber = (j*2);
		stringPressed[j] = (SPI_RX[currentnumber] << 8) + SPI_RX[currentnumber+1];
		//if (stringTouchLH[j] || stringTouchRH[j])
		//{
			//HAL_GPIO_WritePin(GPIOB, GPIO_PIN_4, GPIO_PIN_SET);
		//}

		//if there is more than one pluck data bit waiting for this string, then
		//move the stack toward the first position
		if (stringChangeWaiting[j] > 0)
		{
			for (int i = stringChangeWaiting[j]; i > 1; i--)
			{
				waitingPlucks[j][i-2]  = waitingPlucks[j][i-1];
			}
			stringChangeWaiting[j]--;
		}
		//SPI_TX[j*2+8+(16*spiBuffer)] = (uint8_t) (stringFrozen[j]); //high byte
	}
	SPI_TX[8+(16*spiBuffer)] = 0xfe; //check byte
	SPI_TX[9+(16*spiBuffer)] = 0xfd; //check byte
    SPI_lock = 0;
	//HAL_GPIO_WritePin(GPIOG, GPIO_PIN_10, GPIO_PIN_RESET);

    /*
    while(__HAL_DMA_GET_FLAG(&hdma_spi1_tx,DMA_FLAG_TCIF1_5))
    {
    	HAL_GPIO_TogglePin(GPIOA, GPIO_PIN_0);
    }
    __HAL_DMA_ENABLE(&hdma_spi1_tx);
    */
    HAL_SPI_TransmitReceive_IT(&hspi1, SPI_TX, SPI_RX, 16);
	HAL_GPIO_WritePin(GPIOA, GPIO_PIN_0, GPIO_PIN_RESET);
}
#if 0
void HAL_SPI_TxRxHalfCpltCallback(SPI_HandleTypeDef *hspi)
{
	//HAL_GPIO_WritePin(GPIOB, GPIO_PIN_4, GPIO_PIN_RESET);
	//__HAL_DMA_DISABLE(&hdma_spi1_tx);
	spiBuffer = 0;
   HAL_GPIO_WritePin(GPIOA, GPIO_PIN_0, GPIO_PIN_SET);
   SPI_lock = 1;
	SPI_TX[8+(16*spiBuffer)] = 0x00; //check byte
	SPI_TX[9+(16*spiBuffer)] = 0x00; //check byte
    if (waitingPlucks[0][0] > 0)
    {
    	HAL_GPIO_WritePin(GPIOA, GPIO_PIN_1, GPIO_PIN_SET);
    }
    else
    {
    	HAL_GPIO_WritePin(GPIOA, GPIO_PIN_1, GPIO_PIN_RESET);
    }
	for (int j = 0; j < 4; j++)
	{
		stringTouchRH[j] = (SPI_RX[8] >> j) & 1;
		stringPressed[j] = (SPI_RX[j*2] << 8) + SPI_RX[(j*2)+1];

		SPI_TX[j*2+(16*spiBuffer)] = (uint8_t) (waitingPlucks[j][0] >> 8); //high byte
		SPI_TX[j*2+1+(16*spiBuffer)] = (uint8_t) (waitingPlucks[j][0] & 0xff); //low byte

		//if there is more than one pluck data bit waiting for this string, then
		//move the stack toward the first position
		if (stringChangeWaiting[j] > 0)
		{
			for (int i = stringChangeWaiting[j]; i > 1; i--)
			{
				waitingPlucks[j][i-2]  = waitingPlucks[j][i-1];
			}
			stringChangeWaiting[j]--;
		}
	}
	SPI_TX[8+(16*spiBuffer)] = 0xfe; //check byte
	SPI_TX[9+(16*spiBuffer)] = 0xfd; //check byte

	//HAL_GPIO_WritePin(GPIOG, GPIO_PIN_10, GPIO_PIN_SET);

    SPI_lock = 0;
    /*
    while(__HAL_DMA_GET_FLAG(&hdma_spi1_tx,DMA_FLAG_TCIF1_5))
    {
    	HAL_GPIO_TogglePin(GPIOA, GPIO_PIN_0);
    }
    __HAL_DMA_ENABLE(&hdma_spi1_tx);
    */
	HAL_GPIO_WritePin(GPIOA, GPIO_PIN_0, GPIO_PIN_RESET);
}
#endif
// EXTI Line12 External Interrupt ISR Handler CallBackFun
void HAL_GPIO_EXTI_Callback(uint16_t GPIO_Pin) {
	if (GPIO_Pin == GPIO_PIN_12) // If The INT Source Is EXTI Line12
	{

		if (HAL_GPIO_ReadPin(GPIOC, GPIO_PIN_12) == 0) {
			HAL_SPI_Abort(&hspi1);
			__HAL_SPI_CLEAR_OVRFLAG(&hspi1);
		} else {
			for (int i = 0; i < 32; i++) {
				SPI_TX[i] = i;
			}
			for (int i = 0; i < 8; i++) {
				SPI_TX[i] = 0;
			}
			for (int i = 16; i < 24; i++) {
				SPI_TX[i] = 0;
			}
			HAL_SPI_TransmitReceive_DMA(&hspi1, SPI_TX, SPI_RX, 32);
		}
	}
}

/* USER CODE END 4 */

void Error_Handler(void)
{
  __disable_irq();
  while (1)
  {
  }
}
